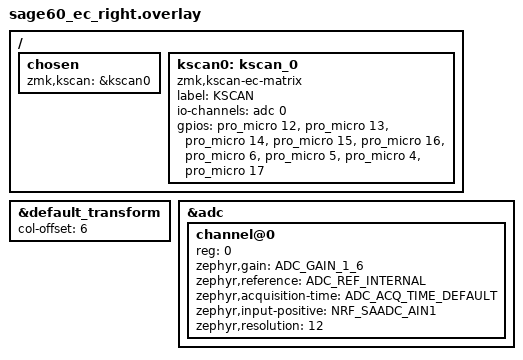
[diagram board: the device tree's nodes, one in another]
/*
 * Copyright (c) 2023 Diwamoto_
 *
 * SPDX-License-Identifier: MIT
 */

#include "sage60_ec.dtsi"

&default_transform {
	col-offset = <6>;
};

/ {
  chosen {
    zmk,kscan = &kscan0;
  };

kscan0: kscan_0 {
	compatible = "zmk,kscan-ec-matrix";
	label = "KSCAN";
	io-channels = <&adc 0>;
	gpios
		= <&pro_micro 12 (GPIO_ACTIVE_HIGH | GPIO_PULL_DOWN)> // row0
		, <&pro_micro 13 (GPIO_ACTIVE_HIGH | GPIO_PULL_DOWN)> // row1
		, <&pro_micro 14 (GPIO_ACTIVE_HIGH | GPIO_PULL_DOWN)> // row2
		, <&pro_micro 15 (GPIO_ACTIVE_HIGH | GPIO_PULL_DOWN)> // row3
		, <&pro_micro 16 (GPIO_ACTIVE_HIGH | GPIO_PULL_DOWN)> // row4
		, <&pro_micro 6 (GPIO_ACTIVE_HIGH | GPIO_PULL_DOWN)> // sel0
		, <&pro_micro 5 (GPIO_ACTIVE_HIGH | GPIO_PULL_DOWN)> // sel1
		, <&pro_micro 4 (GPIO_ACTIVE_HIGH | GPIO_PULL_DOWN)> // sel2
		, <&pro_micro 17 (GPIO_ACTIVE_HIGH | GPIO_PULL_DOWN)> // discharge
		;
};
};

&adc {
  #address-cells = <1>;
  #size-cells = <0>;
  status = "okay";
  channel@0 {
		reg = <0>;
		zephyr,gain = "ADC_GAIN_1_6";
		zephyr,reference = "ADC_REF_INTERNAL";
		zephyr,acquisition-time = <ADC_ACQ_TIME_DEFAULT>;
		zephyr,input-positive = <NRF_SAADC_AIN1>;
		zephyr,resolution = <12>;
	};
};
